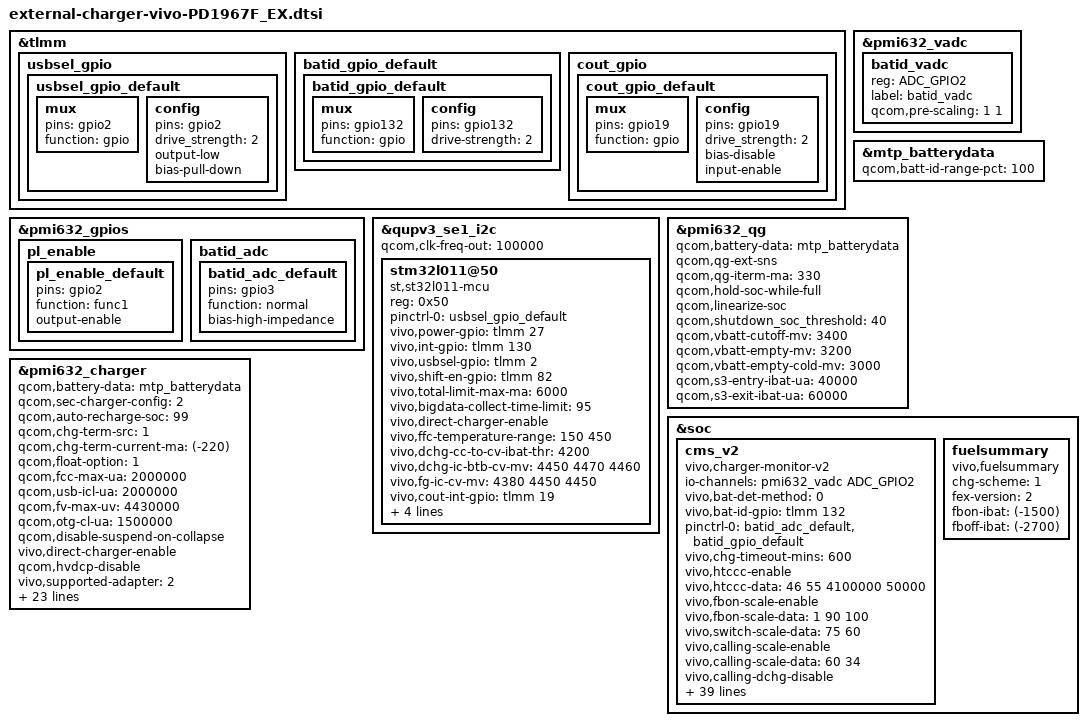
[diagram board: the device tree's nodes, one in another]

&tlmm {
	usbsel_gpio {
		usbsel_gpio_default: usbsel_gpio_default {
			mux {
				pins = "gpio2";
				function = "gpio";
			};

			config {
				pins = "gpio2";
				drive_strength = <2>;
				output-low;
				bias-pull-down; /* pull down */
			};
		};
	};

	batid_gpio_default {
		batid_gpio_default: batid_gpio_default {
			mux {
				pins = "gpio132";
				function = "gpio";
			};
			config {
				pins = "gpio132";
				drive-strength = <2>;
			};
		};
	};
	
	cout_gpio {
 		cout_gpio_default: cout_gpio_default {
			mux {
				pins = "gpio19";
				function = "gpio";
			};

		config {
				pins = "gpio19";
				drive_strength = <2>;
				bias-disable;
				input-enable;
			};
		};
 	};
};
&pmi632_gpios {
	pl_enable {
		pl_enable_default: pl_enable_default {
			pins = "gpio2";
			function = "func1";
			output-enable;
		};
	};
	batid_adc {
		batid_adc_default: batid_adc_default {
			pins = "gpio3";
			function = "normal";
			bias-high-impedance;
		};
	};
};
&pmi632_vadc {
	batid_vadc {
		reg = <ADC_GPIO2>;
		label = "batid_vadc";
		qcom,pre-scaling = <1 1>;
	};
};

&qupv3_se1_i2c {
	status = "ok";
	qcom,clk-freq-out = <100000>;

	stm32l011@50 {
		compatible = "st,st32l011-mcu";
		reg = <0x50>;
		pinctrl-names = "default";
		pinctrl-0 = <&usbsel_gpio_default>;
		vivo,power-gpio = <&tlmm 27 0>;
		vivo,int-gpio = <&tlmm 130 0>;
		vivo,usbsel-gpio = <&tlmm 2 0>;
		vivo,shift-en-gpio = <&tlmm 82 0>;

		vivo,total-limit-max-ma = <6000>;
		vivo,bigdata-collect-time-limit = <95>;	//seconds
		vivo,direct-charger-enable;

		// dual IC + FFC charge:
		//vivo,ffc-support;
		vivo,ffc-temperature-range = <150 450>;
		vivo,dchg-cc-to-cv-ibat-thr = <4200>;	//mA  0.95C 
		vivo,dchg-ic-btb-cv-mv = <4450 4470 4460>;
		vivo,fg-ic-cv-mv = <4380 4450 4450>;

		//dual IC : enable_slave_charger
		//vivo,enable-slave-charger;

		//interrupts = <19 8>;// 8 ?
		//pinctrl-names = "default";
		//pinctrl-0 = <&cout_gpio_default>;
		vivo,cout-int-gpio = <&tlmm 19 0>;

		vivo,bat-temp-exist;

		/*
		DCHG_SUPPORTED_TYPE_22P5W = 0,
		DCHG_SUPPORTED_TYPE_33W = 1,
		DCHG_SUPPORTED_TYPE_44W = 2,
		*/
		vivo,dchg-supported-type = <1>;

		vivo,bat-board-temp-from-bq25970;
		vivo,usb-conn-temp-from-bq25970;

		//vivo,sbu-cable-id-detect-enable;
		 /* SBUx Cable ID ADC */
 		/*io-channels = <&pm8150l_vadc ADC_AMUX_THM1_PU2>,
 					<&pm8150l_vadc ADC_AMUX_THM3_PU2>;
 		io-channel-names = "sbu1_cable_id_adc",
					"sbu2_cable_id_adc";
		*/
	};
};


&mtp_batterydata {
	qcom,batt-id-range-pct = <100>;
	#include "qg-batterydata-PD1957-4880mah.dtsi"
};

&pmi632_qg {
	qcom,battery-data = <&mtp_batterydata>;
	qcom,qg-ext-sns;

	qcom,qg-iterm-ma = <330>;
	qcom,hold-soc-while-full;
	qcom,linearize-soc;
	qcom,shutdown_soc_threshold = <40>;

	qcom,vbatt-cutoff-mv = <3400>;
	qcom,vbatt-empty-mv = <3200>;
	qcom,vbatt-empty-cold-mv = <3000>;

	qcom,s3-entry-ibat-ua = <40000>;
	qcom,s3-exit-ibat-ua = <60000>;
};

&pmi632_charger {
	qcom,battery-data = <&mtp_batterydata>;
	qcom,sec-charger-config = <2>;
	qcom,auto-recharge-soc = <99>;
	qcom,chg-term-src = <1>;
	qcom,chg-term-current-ma = <(-220)>;
	qcom,float-option = <1>;

	qcom,fcc-max-ua = <2000000>;
	qcom,usb-icl-ua = <2000000>;
	qcom,fv-max-uv = <4430000>;
	qcom,otg-cl-ua = <1500000>;
	qcom,disable-suspend-on-collapse;

	vivo,direct-charger-enable;
	//vivo,bms-psy-name = "bq_bms";
	qcom,hvdcp-disable;

	/*
	enum SUPPORTED_ADAPTER {
		SUPPORTED_ADAPTER_DEFAULT = 0,
		SUPPORTED_ADAPTER_VIVO_LV_DCHG_5V_4500MA = 1,
		SUPPORTED_ADAPTER_VIVO_HV_DCHG_10V_2250MA = 2,
		SUPPORTED_ADAPTER_QC20__9V_2000MA = 3,
		SUPPORTED_ADAPTER_VIVO_HV_DCHG_10V_4000MA = 4,
		SUPPORTED_ADAPTER_MAX,
	};
	*/
	vivo,supported-adapter = <2>;
	
	vivo,primary-fastchg-max-ua = <6000000>;
	vivo,parallel-fastchg-max-ua = <0>;
	/* vivo,primary-fastchg-max-ua + vivo,parallel-fastchg-max-ua - 1000 */
	vivo,current_spec_min_ma = <3500>;
	/* vivo,primary-fastchg-max-ua + vivo,parallel-fastchg-max-ua + 100 */
	vivo,current_spec_max_ma = <6100>;
	
	/*ffc cv/iterm*/
	//PMIC reg setting value
	vivo,ffc-chg-term-current-ma = <(-750)>;
	vivo,ffc-fv-max-uv =  <4467000>;
	//Software compare vaule
	vivo,ffc-full-chg-ibat = <(-1351)>;
	vivo,ffc-full-chg-vbat =  <4450000>;
	vivo,ffc-temperature-range = <150 450>;

	
	/*primary board temp & parallel board temp*/
	io-channels = <&pmi632_vadc ADC_USB_IN_V_16>,
		      <&pmi632_vadc ADC_USB_IN_I>,
		      <&pmi632_vadc ADC_CHG_TEMP>,
		      <&pmi632_vadc ADC_DIE_TEMP>,
		      <&pm6125_vadc ADC_AMUX_THM2_PU2>,
		      <&pm6125_vadc ADC_AMUX_THM2_PU2>;
	io-channel-names = "usb_in_voltage",
			   "usb_in_current",
			   "chg_temp",
			   "die_temp",
			   "pri_ntc_temp",
			   "pl_ntc_temp";

	/* pl reuse battery temperature interface */
	//vivo,pl-use-batt-temp-enable;

	/* pl enable gpio config */
	vivo,pl-enable-gpio = <&pmi632_gpios 2 0x00>;
	pinctrl-names = "default";
	pinctrl-0 = <&pl_enable_default>;

	//vivo,usbsel-gpio = <&tlmm 116 0>;
	//vivo,usboe-gpio = <&tlmm 21 0>;

	vivo,soft-term-enable;
	vivo,soft-term-capacity-limit = <100>;
	vivo,soft-term-timer-limit = <30>;//5min

	vivo,tracking_soc_enable;
	vivo,tracking_step_second= <10>;

	/*charge condition force 5v*/
	//vivo,cc-force-5v-soc-limit = <90>;

	/*charge condition force 5v,flashled enable*/
	vivo,cc-force-5v-flashled-enable;

	/*battery temp compensation*/
	//vivo,batt-temp-comp-enable;
};


&soc {
	cms_v2 {
		compatible = "vivo,charger-monitor-v2";

		//vivo,battery-plugable = <0>;//0:unplugable,1:plugable , default:0

		/* battery ID ADC */
		io-channels = <&pmi632_vadc ADC_GPIO2>;
		io-channel-names = "cms_batt_id";

		vivo,bat-det-method = <0>;  //r:0 , rc:1 , eprom:2, ex-fg:3
		vivo,bat-id-gpio = <&tlmm 132 0x00>;
		pinctrl-names = "default";
		pinctrl-0 = <&batid_adc_default &batid_gpio_default>;

		//vivo,no-bat-warning;
		//vivo,no-chg-timeout;
		vivo,chg-timeout-mins = <600>;

		//high temperature charger current control enable
		vivo,htccc-enable;
		vivo,htccc-data = <46 55 4100000 50000>;

		vivo,fbon-scale-enable;
		vivo,fbon-scale-data = <1 90 100>;

		//vivo,switch-scale-enable;
		vivo,switch-scale-data = <75 60>;

		vivo,calling-scale-enable;
		vivo,calling-scale-data = <60 34>;
		vivo,calling-dchg-disable;

		//vivo,fixed-scale-enable;
		vivo,fixed-scale-data = <120 3800 0>;

		//battery voltage compensate
		vivo,vbat-r-comp = <20>;

		/*data processing : batt-temp*/
		//vivo,dp-batt-temp-enable;
		vivo,dp-batt-temp-data = <100>;

		//ibat scale base on temperature
		vivo,normal-tc-row-col = <8 7>;
		vivo,normal-tc-data =
					<550 8888 0 0 0 0 0>,
					<450 549 50 0 0 0 0>,
					<200 449 100 4200000 70 0 0>,
					<150 199 70 0 0 0 0>,
					<100 149 70 4200000 50 0 0>,
					<50 99 30 0 0 0 0>,
					<0 49 30 0 0 0 0>,
					<(-8888) (-1) 0 0 0 0 0>;

		//adjust fastchg base on board temperature and fb off
		//vivo,intell-charge-enable;
		//vivo,parallel-temp-enable = <1 1>;//<x y> x:fb-on y:fb-off
		/*Fast charger intell param*/
		//fb-on param
		vivo,primary-fbon-tc-row-col = <5 3>;
		vivo,primary-fbon-tc-data = <431 8888 1600>,
						    <391 430 3200>,
						    <371 390 4100>,
						    <351 370 4300>,
						    <(-8888) 350 4500>;
		vivo,parallel-fbon-tc-row-col = <1 3>;
		vivo,parallel-fbon-tc-data = <(-8888) 8888 0>;

		//fb-off param
		vivo,primary-fboff-tc-row-col = <5 3>;
		vivo,primary-fboff-tc-data = <411 8888 2800>,
						    <391 410 3200>,
						    <371 390 4000>,
						    <351 370 4300>,
						    <(-8888) 350 4500>;
		vivo,parallel-fboff-tc-row-col = <1 3>;
		vivo,parallel-fboff-tc-data = <(-8888) 8888 0>;

		/*5v Normal charger intell param*/
		//vivo,ex-intell-charge-enable;
		///vivo,ex-parallel-temp-enable = <1 1>;//<x y> x:fb-on y:fb-off
		//fb-on param
		vivo,ex-primary-fbon-tc-row-col = <4 3>;
		vivo,ex-primary-fbon-tc-data = <481 8888 300>,
						    <451 480 600>,
						    <421 450 1000>,
						    <(-8888) 420 2000>;
		vivo,ex-parallel-fbon-tc-row-col = <1 3>;
		vivo,ex-parallel-fbon-tc-data = <(-8888) 8888 0>;

		//fb-off param
		vivo,ex-primary-fboff-tc-row-col = <4 3>;
		vivo,ex-primary-fboff-tc-data = <481 8888 300>,
						    <451 480 600>,
						    <421 450 1000>,
						    <(-8888) 420 2000>;
		vivo,ex-parallel-fboff-tc-row-col = <1 3>;
		vivo,ex-parallel-fboff-tc-data = <(-8888) 8888 0>;

		// Direct charging param
		vivo,direct-charger-enable;
		//vivo,ex-bms-psy-name = "bq_bms";

		// bat_baord, usb_conn, pcb_conn(master_bat_conn), bat_conn
		//vivo,dchg-ntc-protect-enable;
		vivo,dchg-ntc-protect-data = <750 800 850 850>;

		vivo,adapter-cooldown-data = <900 850 3400>;	/* Heat_trigger, Heat_recover, fcc */

		/* usb connecter protect param */
		/*
			enum usb_connecter_protect_type {
					USB_PROTECT_NONE = 0,
					USB_CONN_TEMP_HEAT_PROTECT = BIT(0),
					USB_ID_PROTECT = BIT(1),
			};
		*/
		//vivo,usb-connecter-protect-enable = <1>;
		vivo,usb-id-protect-data= <1100 1547 500>;	/* 500K, 2M, fcc */
		vivo,usb-conn-heat-protect-data-row-col = <2 4>;
		vivo,usb-conn-heat-protect-data= <260 8888 670 620>,
										<(-8888) 259 570 520>;
	};

	fuelsummary {
		compatible = "vivo,fuelsummary";

		/************************************************************
		 *
		 *  0	vivo-fastchg
		 *  1	qcom-dualchg
		 *  2	mtk-dualchg
		 *  3	qcom-normchg
		 *  4	mtk-normchg
		 *
		 ***********************************************************/
		chg-scheme = <1>;
		fex-version = <2>;
		fbon-ibat = <(-1500)>;
		fboff-ibat = <(-2700)>;
	};
};
